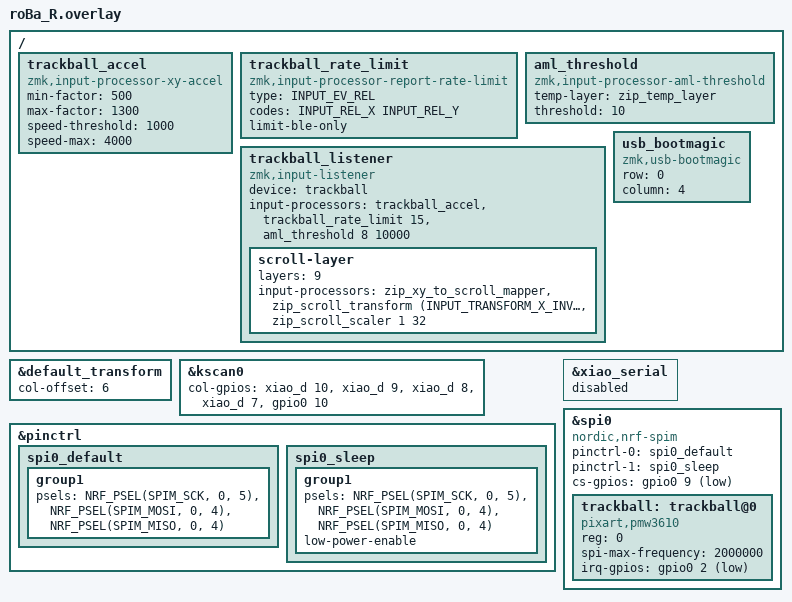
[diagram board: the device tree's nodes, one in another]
#include "roBa.dtsi"
#include <input/processors.dtsi>
#include <dt-bindings/zmk/input_transform.h>
#include <zephyr/dt-bindings/input/input-event-codes.h>

&default_transform {
    col-offset = <6>;
};

&kscan0 {
        col-gpios
            = <&xiao_d 10 GPIO_ACTIVE_HIGH>
            , <&xiao_d 9 GPIO_ACTIVE_HIGH>
            , <&xiao_d 8 GPIO_ACTIVE_HIGH>
            , <&xiao_d 7 GPIO_ACTIVE_HIGH>
            , <&gpio0 10 GPIO_ACTIVE_HIGH>
            ;
};

/ {
    // カーソルの加速 (zmk-input-processor-xy-accel)。LisM と同じ値。ボールを転がす速さ (カウント/秒) に
    // 応じて移動量に倍率 (1000 = 等倍) を掛ける。速さ 0 で min-factor、speed-threshold で等倍、
    // speed-max 以上で max-factor になり、その間は直線で補間する。ゆっくり動かしたときは
    // カーソルを細かく動かし、速く動かしたときは遠くまで動かす。
    // ゆっくり動かしたときに遅すぎれば min-factor を上げ、速く動かしたときに飛びすぎれば
    // (Windows の「ポインターの精度を高める」と重なるときなど) max-factor を下げる (1000 で加速なし)
    trackball_accel: trackball_accel {
        compatible = "zmk,input-processor-xy-accel";
        #input-processor-cells = <0>;
        min-factor = <500>;
        max-factor = <1300>;
        speed-threshold = <1000>;
        speed-max = <4000>;
    };

    // BLE で送るカーソルのレポートを、指定した ms に 1 回までにまとめる (USB 接続中は素通し)。
    // ドライバは 8ms ごと (CONFIG_PMW3610_POLLING_RATE_125_SW) に報告し、ZMK はその 1 回ごとに
    // レポートを 1 つ送る。ほかのキーボードも同じ PC に BLE でつないでいると、送信の機会が足りずに
    // レポートが溜まり、カーソルが遅れてまとめて動く。間隔に満たない X/Y は次のレポートに足す
    // (badjeff/zmk-input-processor-report-rate-limit。KUKEY42 と同じ)。
    // 値は 15: 8ms ごとの報告が 16ms ごとになる。まだカクつくときは 30 (32ms ごと) に上げる
    trackball_rate_limit: trackball_rate_limit {
        compatible = "zmk,input-processor-report-rate-limit";
        #input-processor-cells = <1>;
        type = <INPUT_EV_REL>;
        codes = <INPUT_REL_X INPUT_REL_Y>;
        limit-ble-only;
    };

    // AML の発動条件 (zmk-input-processor-aml-threshold)。LisM と同じ値。リスナーで zip_temp_layer の
    // 代わりに使い、キー入力の振動などでボールがわずかに動いても AML (MOUS) にしない。止まっていた状態から
    // 動いた量 (X と Y それぞれ向き付きで足すので、行ったり来たりする振動は打ち消し合う) の大きさが
    // threshold (加速の後の値 = カーソルの移動量) に達したら zip_temp_layer に渡す。キーを押した・離したあと
    // require-prior-idle-ms (roBa.keymap の zip_temp_layer の値) の間も渡さない。
    // まだ振動で AML になるなら threshold を上げ、少し動かしただけでは AML にならないなら下げる
    aml_threshold: aml_threshold {
        compatible = "zmk,input-processor-aml-threshold";
        #input-processor-cells = <2>;
        temp-layer = <&zip_temp_layer>;
        threshold = <10>;
    };

    // 加速はセンサーの報告間隔のまま速さを測るため、間隔をまとめる前に置く
    trackball_listener {
        status = "okay";
        compatible = "zmk,input-listener";
        device = <&trackball>;

        input-processors =
            <&trackball_accel>,
            <&trackball_rate_limit 15>,
            <&aml_threshold 8 10000>;   // 8 = MOUS (マウス移動レイヤーを自動有効化。わずかな動きでは発動しない)

        // CPI を 400 から 800 に上げたので、1/16 から 1/32 にしてスクロールの速さを保つ
        scroll-layer {
            layers = <9>;
            input-processors =
                <&zip_xy_to_scroll_mapper>,
                <&zip_scroll_transform (INPUT_TRANSFORM_X_INVERT | INPUT_TRANSFORM_Y_INVERT)>,
                <&zip_scroll_scaler 1 32>;
        };
    };
};

&pinctrl {
    spi0_default: spi0_default {
        group1 {
            psels = <NRF_PSEL(SPIM_SCK, 0, 5)>,
                <NRF_PSEL(SPIM_MOSI, 0, 4)>,
                <NRF_PSEL(SPIM_MISO, 0, 4)>;
        };
    };

    spi0_sleep: spi0_sleep {
        group1 {
            psels = <NRF_PSEL(SPIM_SCK, 0, 5)>,
                <NRF_PSEL(SPIM_MOSI, 0, 4)>,
                <NRF_PSEL(SPIM_MISO, 0, 4)>;
            low-power-enable;
        };
    };
};

&xiao_serial { status = "disabled"; };

&spi0 {
    status = "okay";
    compatible = "nordic,nrf-spim";
    pinctrl-0 = <&spi0_default>;
    pinctrl-1 = <&spi0_sleep>;
    pinctrl-names = "default", "sleep";
    cs-gpios = <&gpio0 9 GPIO_ACTIVE_LOW>;

    trackball: trackball@0 {
        status = "okay";
        compatible = "pixart,pmw3610";
        reg = <0>;
        spi-max-frequency = <2000000>;
        irq-gpios = <&gpio0 2 (GPIO_ACTIVE_LOW | GPIO_PULL_UP)>;
    };
};

// P を押したまま USB ケーブルを挿すと、ブートローダになる (src/usb_bootmagic.c)
/ {
    usb_bootmagic {
        compatible = "zmk,usb-bootmagic";
        row = <0>;
        column = <4>;
    };
};
